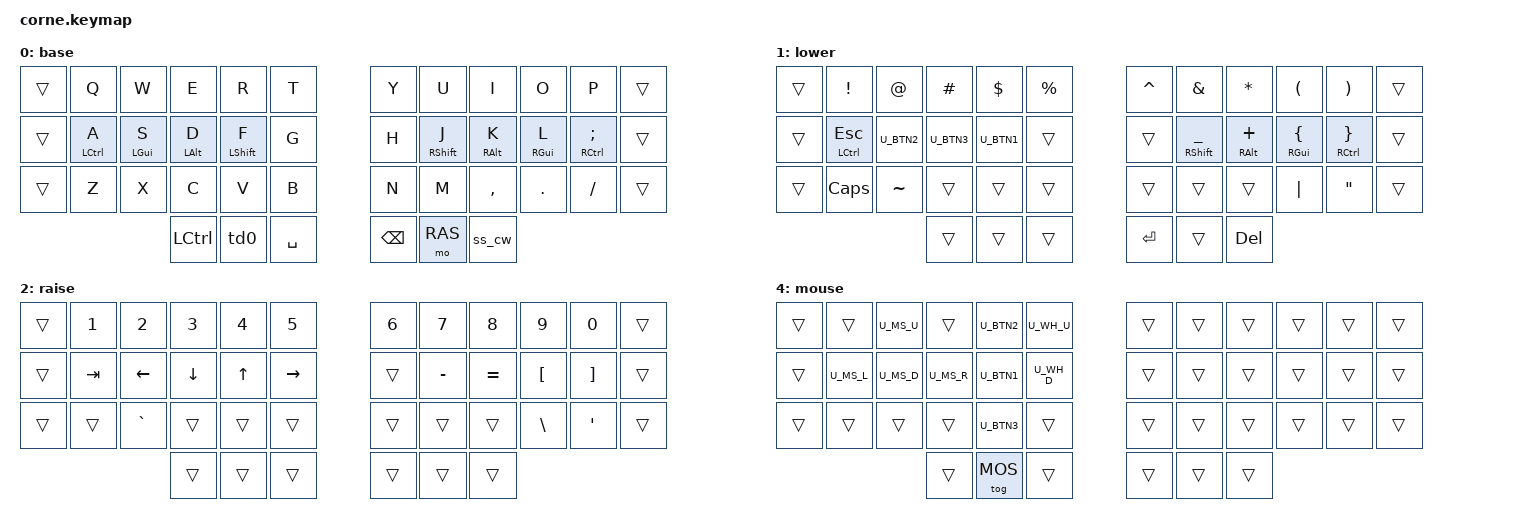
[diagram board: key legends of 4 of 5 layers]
#include <behaviors.dtsi>
#include <dt-bindings/zmk/keys.h>

#include <dt-bindings/zmk/bt.h>
#define _BT_SEL_KEYS_ &bt BT_SEL 0 &bt BT_SEL 1 &bt BT_SEL 2 &bt BT_SEL 3 &bt BT_SEL 4 &bt BT_CLR

#include "../zmk-nodefree-config/helper.h"
#include "../zmk-nodefree-config/keypos_def/keypos_42keys.h"
#include "../zmk-nodefree-config/international_chars/german.dtsi"

/* layer and key shortcuts */

#define ___ &trans

#define DEF 0  // layer shortcuts, must match order in which they are defined below
#define LOW 1
#define RAS 2
#define FUN 3
#define MOS 4

/* custom behaviors */
#include "mouse.dtsi"

// homerow mods
ZMK_BEHAVIOR(hrm, hold_tap,
    flavor = "balanced";
    tapping-term-ms = <280>;
    quick-tap-ms = <125>;
    global-quick-tap;
    bindings = <&kp>, <&kp>;
)

// tap: sticky shift | double tap: capsword
ZMK_BEHAVIOR(ss_cw, tap_dance,
    tapping-term-ms = <200>;
    bindings = <&sk LSHFT>, <&caps_word>;
)

ZMK_BEHAVIOR(td0, tap_dance,
    tapping-term-ms = <200>;
    bindings = <&mo LOW>, <&mo MOS>, <&tog MOS>;
)

// tap: backspace | shift + tap: delete | hold: RAS layer
ZMK_BEHAVIOR(bs_del_num, mod_morph,
    bindings = <&lt RAS BSPC>, <&kp DEL>;
    mods = <(MOD_LSFT|MOD_RSFT)>;
)

// windows sleep macro
ZMK_BEHAVIOR(win_sleep, macro,
    wait-ms = <100>;
    tap-ms = <5>;
    bindings = <&kp LG(X) &kp U &kp S>;
)

// euro sign
ZMK_UNICODE_SINGLE(euro_sign, N2, N0, A, C)  // €

// FUN when LOW and RAS are held jointly
ZMK_CONDITIONAL_LAYER(LOW RAS, FUN)

// combos
#undef COMBO_TERM
#define COMBO_TERM 40  // timeout of 40ms (default is 30ms if omitted)
ZMK_COMBO(combo_sleep,  &win_sleep, RT3 RT4, LOW)  // custom sleep macro, only active on LOW layer
ZMK_COMBO(combo_copy,   &kp LC(C),  LB2 LB3, ALL)  // Ctrl + C, active on all layers
ZMK_COMBO(combo_paste,  &kp LC(V),  LB1 LB2, ALL)  // Ctrl + V, active on all layers

/* keymap */

ZMK_LAYER(base,
     // ╭─────────────┬─────────────┬─────────────┬─────────────┬─────────────┬─────────────╮   ╭─────────────┬─────────────┬─────────────┬─────────────┬─────────────┬─────────────╮
             ___           &kp Q         &kp W         &kp E         &kp R         &kp T             &kp Y         &kp U         &kp I         &kp O         &kp P         ___
     // ├─────────────┼─────────────┼─────────────┼─────────────┼─────────────┼─────────────┤   ├─────────────┼─────────────┼─────────────┼─────────────┼─────────────┼─────────────┤
             ___       &hrm LCTRL A   &hrm LGUI S   &hrm LALT D  &hrm LSHFT F      &kp G             &kp H      &hrm RSHFT J  &hrm RALT K   &hrm RGUI L   &hrm RCTRL SEMI  ___
     // ├─────────────┼─────────────┼─────────────┼─────────────┼─────────────┼─────────────┤   ├─────────────┼─────────────┼─────────────┼─────────────┼─────────────┼─────────────┤
             ___            &kp Z         &kp X         &kp C         &kp V         &kp B             &kp N         &kp M      &kp COMMA     &kp DOT       &kp FSLH        ___
     // ╰─────────────┼─────────────┼─────────────┼─────────────┼─────────────┼─────────────┤   ├─────────────┼─────────────┼─────────────┼─────────────┼─────────────┼─────────────┤
                                                      &kp LCTRL       &td0        &kp SPACE         &kp BSPC      &mo RAS      &ss_cw
     //                                           ╰─────────────┴─────────────┴─────────────╯   ╰─────────────┴─────────────┴─────────────╯              
)

ZMK_LAYER(lower,
     // ╭─────────────┬─────────────┬─────────────┬─────────────┬─────────────┬─────────────╮   ╭─────────────┬─────────────┬─────────────┬─────────────┬─────────────┬─────────────╮
             ___         &kp EXCL      &kp AT        &kp HASH      &kp DLLR      &kp PRCNT         &kp CARET     &kp AMPS      &kp STAR      &kp LPAR      &kp RPAR        ___
     // ├─────────────┼─────────────┼─────────────┼─────────────┼─────────────┼─────────────┤   ├─────────────┼─────────────┼─────────────┼─────────────┼─────────────┼─────────────┤
             ___       &hrm LCTRL ESC   U_BTN2        U_BTN3        U_BTN1          ___               ___   &hrm RSHFT UNDER &hrm RALT PLUS &hrm RGUI LBRC &hrm RCTRL RBRC ___
     // ├─────────────┼─────────────┼─────────────┼─────────────┼─────────────┼─────────────┤   ├─────────────┼─────────────┼─────────────┼─────────────┼─────────────┼─────────────┤
             ___         &kp CAPS      &kp TILDE        ___           ___           ___               ___           ___           ___        &kp PIPE      &kp DQT         ___
     // ╰─────────────┼─────────────┼─────────────┼─────────────┼─────────────┼─────────────┤   ├─────────────┼─────────────┼─────────────┼─────────────┼─────────────┼─────────────┤
                                                        ___           ___           ___              &kp RET        ___        &kp DEL
     //                                           ╰─────────────┴─────────────┴─────────────╯   ╰─────────────┴─────────────┴─────────────╯              
)

ZMK_LAYER(raise,
     // ╭─────────────┬─────────────┬─────────────┬─────────────┬─────────────┬─────────────╮   ╭─────────────┬─────────────┬─────────────┬─────────────┬─────────────┬─────────────╮
             ___          &kp N1        &kp N2        &kp N3        &kp N4        &kp N5            &kp N6        &kp N7        &kp N8        &kp N9        &kp N0         ___
     // ├─────────────┼─────────────┼─────────────┼─────────────┼─────────────┼─────────────┤   ├─────────────┼─────────────┼─────────────┼─────────────┼─────────────┼─────────────┤
             ___          &kp TAB       &kp LEFT      &kp DOWN      &kp UP        &kp RIGHT           ___         &kp MINUS     &kp EQUAL     &kp LBKT      &kp RBKT       ___
     // ├─────────────┼─────────────┼─────────────┼─────────────┼─────────────┼─────────────┤   ├─────────────┼─────────────┼─────────────┼─────────────┼─────────────┼─────────────┤
             ___            ___         &kp GRAVE       ___           ___           ___               ___           ___           ___         &kp BSLH      &kp SQT        ___
     // ╰─────────────┼─────────────┼─────────────┼─────────────┼─────────────┼─────────────┤   ├─────────────┼─────────────┼─────────────┼─────────────┼─────────────┼─────────────┤
                                                        ___           ___           ___               ___           ___           ___                                         
     //                                           ╰─────────────┴─────────────┴─────────────╯   ╰─────────────┴─────────────┴─────────────╯              
)

ZMK_LAYER(func,
     // ╭─────────────┬─────────────┬─────────────┬─────────────┬─────────────┬─────────────╮   ╭─────────────┬─────────────┬─────────────┬─────────────┬─────────────┬─────────────╮
             ___           &kp F1        &kp F2        &kp F3        &kp F4        &kp F5            &kp F6        &kp F7        &kp F8        &kp F9        &kp F10       ___
     // ├─────────────┼─────────────┼─────────────┼─────────────┼─────────────┼─────────────┤   ├─────────────┼─────────────┼─────────────┼─────────────┼─────────────┼─────────────┤
             ___           &kp F11      &kp F12         ___           ___           ___               ___           ___           ___           ___           ___          ___
     // ├─────────────┼─────────────┼─────────────┼─────────────┼─────────────┼─────────────┤   ├─────────────┼─────────────┼─────────────┼─────────────┼─────────────┼─────────────┤
                                     _BT_SEL_KEYS_                                                    ___           ___           ___           ___           ___          ___
     // ╰─────────────┼─────────────┼─────────────┼─────────────┼─────────────┼─────────────┤   ├─────────────┼─────────────┼─────────────┼─────────────┼─────────────┼─────────────┤
                                                        ___           ___           ___               ___           ___           ___                                         
     //                                           ╰─────────────┴─────────────┴─────────────╯   ╰─────────────┴─────────────┴─────────────╯              
)

ZMK_LAYER(mouse,
     // ╭─────────────┬─────────────┬─────────────┬─────────────┬─────────────┬─────────────╮   ╭─────────────┬─────────────┬─────────────┬─────────────┬─────────────┬─────────────╮
             ___            ___          U_MS_U         ___          U_BTN2       U_WH_U              ___           ___           ___           ___           ___          ___
     // ├─────────────┼─────────────┼─────────────┼─────────────┼─────────────┼─────────────┤   ├─────────────┼─────────────┼─────────────┼─────────────┼─────────────┼─────────────┤
             ___           U_MS_L       U_MS_D        U_MS_R         U_BTN1       U_WH_D              ___           ___           ___           ___           ___          ___
     // ├─────────────┼─────────────┼─────────────┼─────────────┼─────────────┼─────────────┤   ├─────────────┼─────────────┼─────────────┼─────────────┼─────────────┼─────────────┤
             ___            ___           ___           ___          U_BTN3         ___               ___           ___           ___           ___           ___          ___
     // ╰─────────────┼─────────────┼─────────────┼─────────────┼─────────────┼─────────────┤   ├─────────────┼─────────────┼─────────────┼─────────────┼─────────────┼─────────────┤
                                                        ___          &tog MOS       ___               ___           ___           ___
     //                                           ╰─────────────┴─────────────┴─────────────╯   ╰─────────────┴─────────────┴─────────────╯              
)

